# STM32L5x2 register map
File version: 1.3
Registers are 32-bit, read-write, reset 0x0 unless marked. A register's access mark holds for its fields unless they carry their own. Offsets are from the block's base; [hi:lo] are bit positions; {n}, {i} and the like mark numbered series.

## TZSC
Base 0x40032400
Same registers: SEC_TZSC 0x50032400
0x00 TZSC_CR — TZSC control register
  [0] LCK
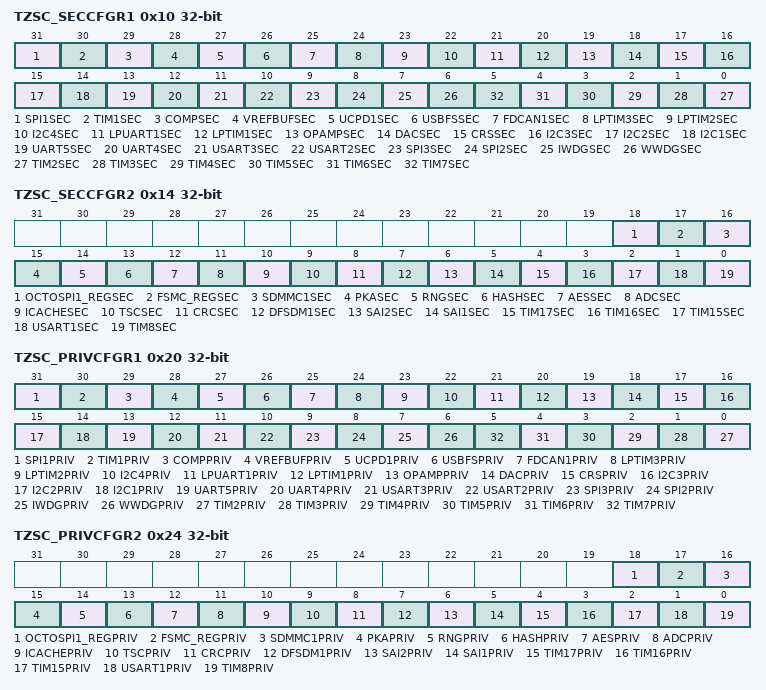
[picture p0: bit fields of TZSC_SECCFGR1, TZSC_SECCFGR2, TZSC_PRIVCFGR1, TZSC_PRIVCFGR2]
0x10 TZSC_SECCFGR1 — TZSC secure configuration register 1
  [31] SPI1SEC, [30] TIM1SEC, [29] COMPSEC, [28] VREFBUFSEC, [27] UCPD1SEC, [26] USBFSSEC, [25] FDCAN1SEC, [24] LPTIM3SEC, [23] LPTIM2SEC, [22] I2C4SEC, [21] LPUART1SEC, [20] LPTIM1SEC, [19] OPAMPSEC, [18] DACSEC, [17] CRSSEC, [16] I2C3SEC, [15] I2C2SEC, [14] I2C1SEC, [13] UART5SEC, [12] UART4SEC, [11] USART3SEC, [10] USART2SEC, [9] SPI3SEC, [8] SPI2SEC, [7] IWDGSEC, [6] WWDGSEC, [n-2] TIM{n}SEC (n=2..7)
0x14 TZSC_SECCFGR2 — TZSC secure configuration register 2
  [18] OCTOSPI1_REGSEC, [17] FSMC_REGSEC, [16] SDMMC1SEC, [15] PKASEC, [14] RNGSEC, [13] HASHSEC, [12] AESSEC, [11] ADCSEC, [10] ICACHESEC, [9] TSCSEC, [8] CRCSEC, [7] DFSDM1SEC, [6] SAI2SEC, [5] SAI1SEC, [4] TIM17SEC, [3] TIM16SEC, [2] TIM15SEC, [1] USART1SEC, [0] TIM8SEC
0x20 TZSC_PRIVCFGR1 — TZSC privilege configuration register 1
  [31] SPI1PRIV, [30] TIM1PRIV, [29] COMPPRIV, [28] VREFBUFPRIV, [27] UCPD1PRIV, [26] USBFSPRIV, [25] FDCAN1PRIV, [24] LPTIM3PRIV, [23] LPTIM2PRIV, [22] I2C4PRIV, [21] LPUART1PRIV, [20] LPTIM1PRIV, [19] OPAMPPRIV, [18] DACPRIV, [17] CRSPRIV, [16] I2C3PRIV, [15] I2C2PRIV, [14] I2C1PRIV, [13] UART5PRIV, [12] UART4PRIV, [11] USART3PRIV, [10] USART2PRIV, [9] SPI3PRIV, [8] SPI2PRIV, [7] IWDGPRIV, [6] WWDGPRIV, [n-2] TIM{n}PRIV (n=2..7)
0x24 TZSC_PRIVCFGR2 — TZSC privilege configuration register 2
  [18] OCTOSPI1_REGPRIV — OCTOSPI1_REGRIV
  [17] FSMC_REGPRIV
  [16] SDMMC1PRIV
  [15] PKAPRIV
  [14] RNGPRIV
  [13] HASHPRIV
  [12] AESPRIV
  [11] ADCPRIV
  [10] ICACHEPRIV
  [9] TSCPRIV
  [8] CRCPRIV
  [7] DFSDM1PRIV
  [6] SAI2PRIV
  [5] SAI1PRIV
  [4] TIM17PRIV
  [3] TIM16PRIV
  [2] TIM15PRIV
  [1] USART1PRIV
  [0] TIM8PRIV
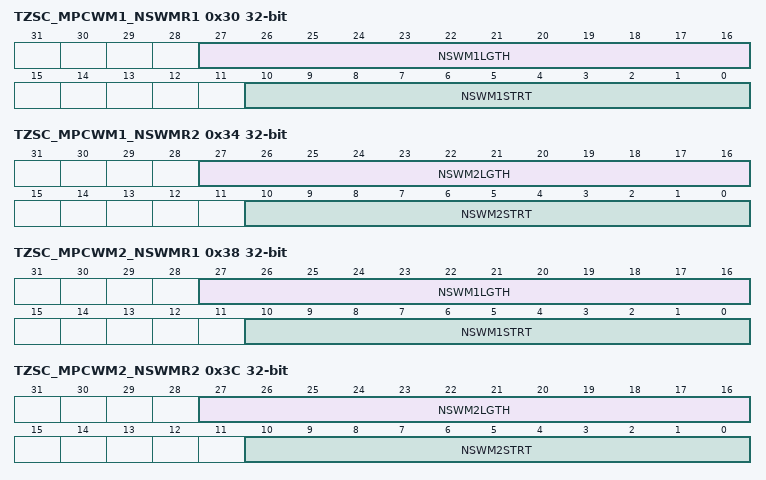
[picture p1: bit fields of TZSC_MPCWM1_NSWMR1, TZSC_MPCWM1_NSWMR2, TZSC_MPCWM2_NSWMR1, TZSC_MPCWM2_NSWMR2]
0x30 TZSC_MPCWM1_NSWMR1 — TZSC external memory non-secure watermark register 1
  [27:16] NSWM1LGTH, [10:0] NSWM1STRT
0x34 TZSC_MPCWM1_NSWMR2 — TZSC external memory non-secure watermark register 1
  [27:16] NSWM2LGTH, [10:0] NSWM2STRT
0x38 TZSC_MPCWM2_NSWMR1 — TZSC external memory non-secure watermark register 1
  [27:16] NSWM1LGTH, [10:0] NSWM1STRT
0x3C TZSC_MPCWM2_NSWMR2 — TZSC external memory non-secure watermark register 2
  [27:16] NSWM2LGTH, [10:0] NSWM2STRT
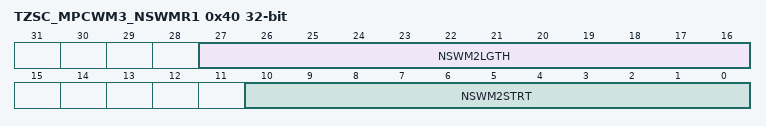
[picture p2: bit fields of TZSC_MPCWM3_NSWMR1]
0x40 TZSC_MPCWM3_NSWMR1 — TZSC external memory non-secure watermark register 2
  [27:16] NSWM2LGTH, [10:0] NSWM2STRT

## WWDG — System window watchdog
Base 0x40002C00
Same registers: SEC_WWDG 0x50002C00
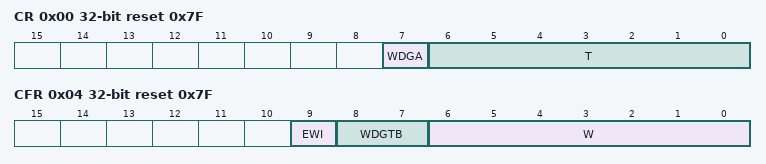
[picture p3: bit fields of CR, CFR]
0x00 CR reset 0x7F — Control register
  [7] WDGA — Activation bit
  [6:0] T — 7-bit counter (MSB to LSB)
0x04 CFR reset 0x7F — Configuration register
  [9] EWI — Early wakeup interrupt
  [8:7] WDGTB — Timer base
  [6:0] W — 7-bit window value
0x08 SR — Status register
  [0] EWIF — Early wakeup interrupt flag

## SYSCFG — System configuration controller
Base 0x40010000
Same registers: SEC_SYSCFG 0x50010000
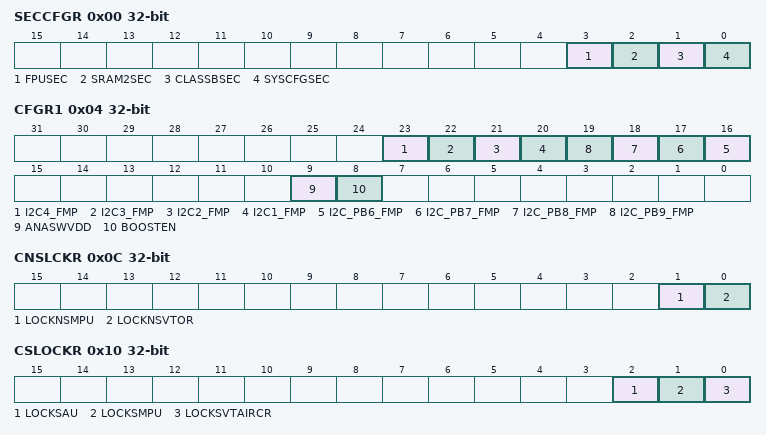
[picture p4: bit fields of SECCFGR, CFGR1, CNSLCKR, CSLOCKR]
0x00 SECCFGR — SYSCFG secure configuration register
  [3] FPUSEC
  [2] SRAM2SEC — SRAM2 security
  [1] CLASSBSEC — ClassB security
  [0] SYSCFGSEC — SYSCFG clock control security
0x04 CFGR1 — configuration register 1
  [23] I2C4_FMP
  [22] I2C3_FMP — I2C3 Fast-mode Plus driving capability activation
  [21] I2C2_FMP — I2C2 Fast-mode Plus driving capability activation
  [20] I2C1_FMP — I2C1 Fast-mode Plus driving capability activation
  [n+10] I2C_PB{n}_FMP (n=6..9) — Fast-mode Plus (Fm+) driving capability activation on PB{n}
  [9] ANASWVDD — GPIO analog switch control voltage selection
  [8] BOOSTEN — I/O analog switch voltage booster enable
0x08 FPUIMR reset 0x1F — FPU interrupt mask register
  [5:0] FPU_IE — Floating point unit interrupts enable bits
0x0C CNSLCKR — SYSCFG CPU non-secure lock register
  [1] LOCKNSMPU — Non-secure MPU registers lock
  [0] LOCKNSVTOR — VTOR_NS register lock
0x10 CSLOCKR — SYSCFG CPU secure lock register
  [2] LOCKSAU, [1] LOCKSMPU, [0] LOCKSVTAIRCR
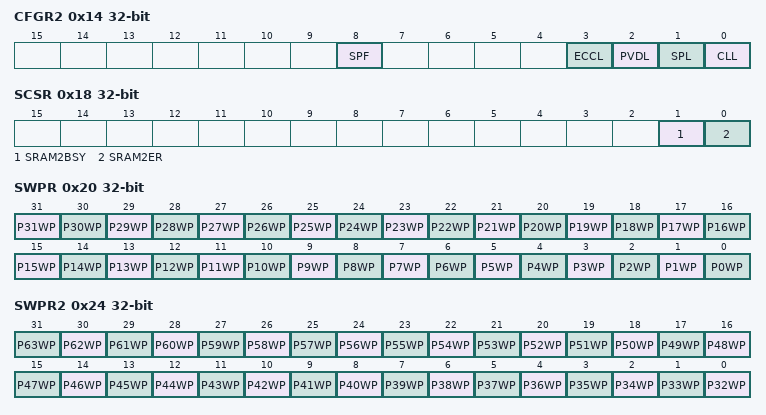
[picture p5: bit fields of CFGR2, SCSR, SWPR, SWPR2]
0x14 CFGR2 access per field
  [8] SPF rw — SRAM2 parity error flag
  [3] ECCL wo — ECC Lock
  [2] PVDL wo — PVD lock enable bit
  [1] SPL wo — SRAM2 parity lock bit
  [0] CLL wo — LOCKUP (hardfault) output enable bit
0x18 SCSR access per field
  [1] SRAM2BSY ro — SRAM2 busy by erase operation
  [0] SRAM2ER rw — SRAM2 Erase
0x1C SKR wo
  [7:0] KEY — SRAM2 write protection key for software erase
0x20 SWPR wo
  [31] P31WP — SRAM2 page 31 write protection
  [n] P{n}WP (n=0..30)
0x24 SWPR2 wo
  [n-32] P{n}WP (n=32..63)
0x2C RSSCMDR
  [7:0] RSSCMD — RSS commands
